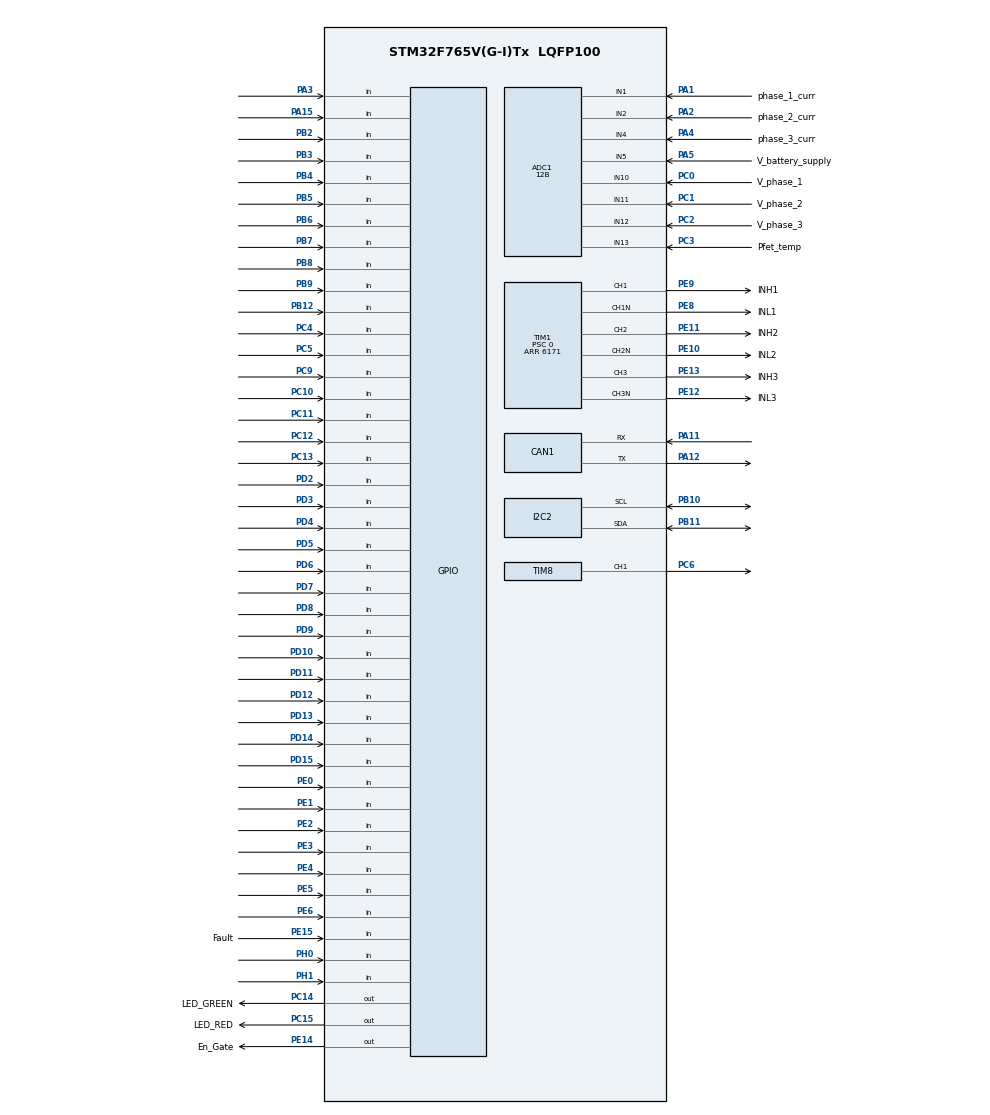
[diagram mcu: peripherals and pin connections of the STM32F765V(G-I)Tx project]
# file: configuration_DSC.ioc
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ADC1.Channel-0\#ChannelRegularConversion=ADC_CHANNEL_1
ADC1.Channel-1\#ChannelRegularConversion=ADC_CHANNEL_1
ADC1.Channel-2\#ChannelRegularConversion=ADC_CHANNEL_1
ADC1.Channel-3\#ChannelRegularConversion=ADC_CHANNEL_1
ADC1.Channel-4\#ChannelRegularConversion=ADC_CHANNEL_1
ADC1.Channel-5\#ChannelRegularConversion=ADC_CHANNEL_1
ADC1.Channel-6\#ChannelRegularConversion=ADC_CHANNEL_1
ADC1.Channel-7\#ChannelRegularConversion=ADC_CHANNEL_1
ADC1.EOCSelection=ADC_EOC_SEQ_CONV
ADC1.ExternalTrigConv=ADC_EXTERNALTRIGCONV_T8_TRGO
ADC1.ExternalTrigConvEdge=ADC_EXTERNALTRIGCONVEDGE_FALLING
ADC1.NbrOfConversion=8
ADC1.NbrOfConversionFlag=1
ADC1.Rank-0\#ChannelRegularConversion=1
ADC1.Rank-1\#ChannelRegularConversion=2
ADC1.Rank-2\#ChannelRegularConversion=3
ADC1.Rank-3\#ChannelRegularConversion=4
ADC1.Rank-4\#ChannelRegularConversion=5
ADC1.Rank-5\#ChannelRegularConversion=6
ADC1.Rank-6\#ChannelRegularConversion=7
ADC1.Rank-7\#ChannelRegularConversion=8
ADC1.Resolution=ADC_RESOLUTION_12B
ADC1.SamplingTime-0\#ChannelRegularConversion=ADC_SAMPLETIME_3CYCLES
ADC1.SamplingTime-1\#ChannelRegularConversion=ADC_SAMPLETIME_3CYCLES
ADC1.SamplingTime-2\#ChannelRegularConversion=ADC_SAMPLETIME_3CYCLES
ADC1.SamplingTime-3\#ChannelRegularConversion=ADC_SAMPLETIME_3CYCLES
ADC1.SamplingTime-4\#ChannelRegularConversion=ADC_SAMPLETIME_3CYCLES
ADC1.SamplingTime-5\#ChannelRegularConversion=ADC_SAMPLETIME_3CYCLES
ADC1.SamplingTime-6\#ChannelRegularConversion=ADC_SAMPLETIME_3CYCLES
ADC1.SamplingTime-7\#ChannelRegularConversion=ADC_SAMPLETIME_3CYCLES
ADC1.master=1
CAN1.CalculateTimeQuantum=1000.0
Dma.ADC1.0.Direction=DMA_PERIPH_TO_MEMORY
Dma.ADC1.0.FIFOMode=DMA_FIFOMODE_DISABLE
Dma.ADC1.0.Instance=DMA2_Stream0
Dma.ADC1.0.MemDataAlignment=DMA_MDATAALIGN_HALFWORD
Dma.ADC1.0.MemInc=DMA_MINC_ENABLE
Dma.ADC1.0.Mode=DMA_CIRCULAR
Dma.ADC1.0.PeriphDataAlignment=DMA_PDATAALIGN_HALFWORD
Dma.ADC1.0.PeriphInc=DMA_PINC_DISABLE
Dma.ADC1.0.Priority=DMA_PRIORITY_HIGH
Dma.Request0=ADC1
Mcu.Family=STM32F7
Mcu.Name=STM32F765V(G-I)Tx
Mcu.Package=LQFP100
NVIC.ADC_IRQn=true\:0\:0\:false\:false\:true\:true\:true
NVIC.DMA2_Stream0_IRQn=true\:0\:0\:false\:false\:true\:false\:true
NVIC.PriorityGroup=NVIC_PRIORITYGROUP_4
PA1.GPIO_Label=phase_1_curr
PA1.Signal=ADCx_IN1
PA11.Mode=Master
PA11.Signal=CAN1_RX
PA12.Mode=Master
PA12.Signal=CAN1_TX
PA13.Signal=SYS_JTMS-SWDIO
PA14.Signal=SYS_JTCK-SWCLK
PA15.GPIO_PuPd=GPIO_PULLDOWN
PA15.Signal=GPIO_Input
PA2.GPIO_Label=phase_2_curr
PA2.Signal=ADCx_IN2
PA3.GPIO_PuPd=GPIO_PULLDOWN
PA3.Signal=GPIO_Input
PA4.GPIO_Label=phase_3_curr
PA4.Signal=ADCx_IN4
PA5.GPIO_Label=V_battery_supply
PA5.Signal=ADCx_IN5
PB10.Mode=I2C
PB10.Signal=I2C2_SCL
PB11.Mode=I2C
PB11.Signal=I2C2_SDA
PB12.GPIO_PuPd=GPIO_PULLDOWN
PB12.Signal=GPIO_Input
PB2.GPIO_PuPd=GPIO_PULLDOWN
PB2.Signal=GPIO_Input
PB3.GPIO_PuPd=GPIO_PULLDOWN
PB3.Signal=GPIO_Input
PB4.GPIO_PuPd=GPIO_PULLDOWN
PB4.Signal=GPIO_Input
PB5.GPIO_PuPd=GPIO_PULLDOWN
PB5.Signal=GPIO_Input
PB6.GPIO_PuPd=GPIO_PULLDOWN
PB6.Signal=GPIO_Input
PB7.GPIO_PuPd=GPIO_PULLDOWN
PB7.Signal=GPIO_Input
PB8.GPIO_PuPd=GPIO_PULLDOWN
PB8.Signal=GPIO_Input
PB9.GPIO_PuPd=GPIO_PULLDOWN
PB9.Signal=GPIO_Input
PC0.GPIO_Label=V_phase_1
PC0.Signal=ADCx_IN10
PC1.GPIO_Label=V_phase_2
PC1.Signal=ADCx_IN11
PC10.GPIO_PuPd=GPIO_PULLDOWN
PC10.Signal=GPIO_Input
PC11.GPIO_PuPd=GPIO_PULLDOWN
PC11.Signal=GPIO_Input
PC12.GPIO_PuPd=GPIO_PULLDOWN
PC12.Signal=GPIO_Input
PC13.GPIO_PuPd=GPIO_PULLDOWN
PC13.Signal=GPIO_Input
PC14/OSC32_IN.GPIO_Label=LED_GREEN
PC14/OSC32_IN.GPIO_PuPd=GPIO_PULLUP
PC14/OSC32_IN.Signal=GPIO_Output
PC15/OSC32_OUT.GPIO_Label=LED_RED
PC15/OSC32_OUT.GPIO_PuPd=GPIO_PULLUP
PC15/OSC32_OUT.Signal=GPIO_Output
PC2.GPIO_Label=V_phase_3
PC2.Signal=ADCx_IN12
PC3.GPIO_Label=Pfet_temp
PC3.Signal=ADCx_IN13
PC4.GPIO_PuPd=GPIO_PULLDOWN
PC4.Signal=GPIO_Input
PC5.GPIO_PuPd=GPIO_PULLDOWN
PC5.Signal=GPIO_Input
PC6.Signal=S_TIM8_CH1
PC9.GPIO_PuPd=GPIO_PULLDOWN
PC9.Signal=GPIO_Input
PD10.GPIO_PuPd=GPIO_PULLDOWN
PD10.Signal=GPIO_Input
PD11.GPIO_PuPd=GPIO_PULLDOWN
PD11.Signal=GPIO_Input
PD12.GPIO_PuPd=GPIO_PULLDOWN
PD12.Signal=GPIO_Input
PD13.GPIO_PuPd=GPIO_PULLDOWN
PD13.Signal=GPIO_Input
PD14.Signal=GPIO_Input
PD15.GPIO_PuPd=GPIO_PULLDOWN
PD15.Signal=GPIO_Input
PD2.GPIO_PuPd=GPIO_PULLDOWN
PD2.Signal=GPIO_Input
PD3.GPIO_PuPd=GPIO_PULLDOWN
PD3.Signal=GPIO_Input
PD4.GPIO_PuPd=GPIO_PULLDOWN
PD4.Signal=GPIO_Input
PD5.GPIO_PuPd=GPIO_PULLDOWN
PD5.Signal=GPIO_Input
PD6.GPIO_PuPd=GPIO_PULLDOWN
PD6.Signal=GPIO_Input
PD7.GPIO_PuPd=GPIO_PULLDOWN
PD7.Signal=GPIO_Input
PD8.GPIO_PuPd=GPIO_PULLDOWN
PD8.Signal=GPIO_Input
PD9.GPIO_PuPd=GPIO_PULLDOWN
PD9.Signal=GPIO_Input
PE0.GPIO_PuPd=GPIO_PULLDOWN
PE0.Signal=GPIO_Input
PE1.GPIO_PuPd=GPIO_PULLDOWN
PE1.Signal=GPIO_Input
PE10.GPIO_Label=INL2
PE10.Mode=PWM Generation2 CH2 CH2N
PE10.Signal=TIM1_CH2N
PE11.GPIO_Label=INH2
PE11.Signal=S_TIM1_CH2
PE12.GPIO_Label=INL3
PE12.Mode=PWM Generation3 CH3 CH3N
PE12.Signal=TIM1_CH3N
PE13.GPIO_Label=INH3
PE13.Signal=S_TIM1_CH3
PE14.GPIO_Label=En_Gate
PE14.GPIO_PuPd=GPIO_PULLUP
PE14.Signal=GPIO_Output
PE15.GPIO_Label=Fault
PE15.GPIO_PuPd=GPIO_PULLUP
PE15.Signal=GPIO_Input
PE2.GPIO_PuPd=GPIO_PULLDOWN
PE2.Signal=GPIO_Input
PE3.GPIO_PuPd=GPIO_PULLDOWN
PE3.Signal=GPIO_Input
PE4.GPIO_PuPd=GPIO_PULLDOWN
PE4.Signal=GPIO_Input
PE5.GPIO_PuPd=GPIO_PULLDOWN
PE5.Signal=GPIO_Input
PE6.GPIO_PuPd=GPIO_PULLDOWN
PE6.Signal=GPIO_Input
PE8.GPIO_Label=INL1
PE8.Mode=PWM Generation1 CH1 CH1N
PE8.Signal=TIM1_CH1N
PE9.GPIO_Label=INH1
PE9.Signal=S_TIM1_CH1
PH0/OSC_IN.GPIO_PuPd=GPIO_PULLDOWN
PH0/OSC_IN.Signal=GPIO_Input
PH1/OSC_OUT.GPIO_PuPd=GPIO_PULLDOWN
PH1/OSC_OUT.Signal=GPIO_Input
ProjectManager.HeapSize=0x200
ProjectManager.StackSize=0x400
ProjectManager.TargetToolchain=STM32CubeIDE
RCC.HSE_VALUE=25000000
RCC.HSI_VALUE=16000000
RCC.LSE_VALUE=32768
RCC.USBFreq_Value=96000000
RCC.VCOOutputFreq_Value=192000000
SH.ADCx_IN1.0=ADC1_IN1,IN1
SH.ADCx_IN10.0=ADC1_IN10,IN10
SH.ADCx_IN11.0=ADC1_IN11,IN11
SH.ADCx_IN12.0=ADC1_IN12,IN12
SH.ADCx_IN13.0=ADC1_IN13,IN13
SH.ADCx_IN2.0=ADC1_IN2,IN2
SH.ADCx_IN4.0=ADC1_IN4,IN4
SH.ADCx_IN5.0=ADC1_IN5,IN5
SH.S_TIM1_CH1.0=TIM1_CH1,PWM Generation1 CH1 CH1N
SH.S_TIM1_CH2.0=TIM1_CH2,PWM Generation2 CH2 CH2N
SH.S_TIM1_CH3.0=TIM1_CH3,PWM Generation3 CH3 CH3N
SH.S_TIM8_CH1.0=TIM8_CH1,Forced Output1 CH1
TIM1.Channel-PWM\ Generation1\ CH1\ CH1N=TIM_CHANNEL_1
TIM1.Channel-PWM\ Generation2\ CH2\ CH2N=TIM_CHANNEL_2
TIM1.Channel-PWM\ Generation3\ CH3\ CH3N=TIM_CHANNEL_3
TIM1.CounterMode=TIM_COUNTERMODE_UP
TIM1.DeadTime=78
TIM1.OCIdleState_1=TIM_OCIDLESTATE_SET
TIM1.OCIdleState_2=TIM_OCIDLESTATE_SET
TIM1.OCIdleState_3=TIM_OCIDLESTATE_SET
TIM1.OCNIdleState_1=TIM_OCNIDLESTATE_SET
TIM1.OCNIdleState_2=TIM_OCNIDLESTATE_SET
TIM1.OCNIdleState_3=TIM_OCNIDLESTATE_SET
TIM1.OffStateIDLEMode=TIM_OSSI_ENABLE
TIM1.OffStateRunMode=TIM_OSSR_ENABLE
TIM1.Period=6171
TIM1.Prescaler=0
TIM1.Pulse-PWM\ Generation1\ CH1\ CH1N=3085
TIM1.Pulse-PWM\ Generation2\ CH2\ CH2N=3085
TIM1.Pulse-PWM\ Generation3\ CH3\ CH3N=3085
TIM8.Channel-Forced\ Output1\ CH1=TIM_CHANNEL_1
TIM8.Period=0xffff
VP_TIM1_VS_ClockSourceINT.Mode=Internal
VP_TIM8_VS_ClockSourceITR.Mode=TriggerSource_ITR0
VP_TIM8_VS_ControllerModeReset.Mode=Reset Mode
board=custom

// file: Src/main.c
/* USER CODE BEGIN Header */
/**
  ******************************************************************************
  * @file           : main.c
  * @brief          : Main program body
  ******************************************************************************
  * @attention
  *
  * <h2><center>&copy; Copyright (c) 2019 STMicroelectronics.
  * All rights reserved.</center></h2>
  *
  * This software component is licensed by ST under BSD 3-Clause license,
  * the "License"; You may not use this file except in compliance with the
  * License. You may obtain a copy of the License at:
  *                        opensource.org/licenses/BSD-3-Clause
  *
  ******************************************************************************
  */
/* USER CODE END Header */

#include "main.h"

ADC_HandleTypeDef hadc1;
DMA_HandleTypeDef hdma_adc1;

CAN_HandleTypeDef hcan1;

I2C_HandleTypeDef hi2c2;

TIM_HandleTypeDef htim1;
TIM_HandleTypeDef htim8;

void SystemClock_Config(void);
static void MX_GPIO_Init(void);
static void MX_DMA_Init(void);
static void MX_ADC1_Init(void);
static void MX_CAN1_Init(void);
static void MX_I2C2_Init(void);
static void MX_TIM1_Init(void);
static void MX_TIM8_Init(void);

int main(void)
{

  /* MCU Configuration--------------------------------------------------------*/

  /* Reset of all peripherals, Initializes the Flash interface and the Systick. */
  HAL_Init();

  /* Configure the system clock */
  SystemClock_Config();

  /* Initialize all configured peripherals */
  MX_GPIO_Init();
  MX_DMA_Init();
  MX_ADC1_Init();
  MX_CAN1_Init();
  MX_I2C2_Init();
  MX_TIM1_Init();
  MX_TIM8_Init();

  /* Infinite loop */
  /* USER CODE BEGIN WHILE */

  //Communicate with other micro-controllers and determine that they are online and functioning
  //Do calibration process than wait to get up to speed.
  //

  while (1)
  {
    /* USER CODE END WHILE */

  }
}

void SystemClock_Config(void)
{
  RCC_OscInitTypeDef RCC_OscInitStruct = {0};
  RCC_ClkInitTypeDef RCC_ClkInitStruct = {0};
  RCC_PeriphCLKInitTypeDef PeriphClkInitStruct = {0};

  /** Configure the main internal regulator output voltage
  */
  __HAL_RCC_PWR_CLK_ENABLE();
  __HAL_PWR_VOLTAGESCALING_CONFIG(PWR_REGULATOR_VOLTAGE_SCALE3);
  /** Initializes the CPU, AHB and APB busses clocks
  */
  RCC_OscInitStruct.OscillatorType = RCC_OSCILLATORTYPE_HSI;
  RCC_OscInitStruct.HSIState = RCC_HSI_ON;
  RCC_OscInitStruct.HSICalibrationValue = RCC_HSICALIBRATION_DEFAULT;
  RCC_OscInitStruct.PLL.PLLState = RCC_PLL_NONE;
  if (HAL_RCC_OscConfig(&RCC_OscInitStruct) != HAL_OK)
  {
    Error_Handler();
  }
  /** Initializes the CPU, AHB and APB busses clocks
  */
  RCC_ClkInitStruct.ClockType = RCC_CLOCKTYPE_HCLK|RCC_CLOCKTYPE_SYSCLK
                              |RCC_CLOCKTYPE_PCLK1|RCC_CLOCKTYPE_PCLK2;
  RCC_ClkInitStruct.SYSCLKSource = RCC_SYSCLKSOURCE_HSI;
  RCC_ClkInitStruct.AHBCLKDivider = RCC_SYSCLK_DIV1;
  RCC_ClkInitStruct.APB1CLKDivider = RCC_HCLK_DIV1;
  RCC_ClkInitStruct.APB2CLKDivider = RCC_HCLK_DIV1;

  if (HAL_RCC_ClockConfig(&RCC_ClkInitStruct, FLASH_LATENCY_0) != HAL_OK)
  {
    Error_Handler();
  }
  PeriphClkInitStruct.PeriphClockSelection = RCC_PERIPHCLK_I2C2;
  PeriphClkInitStruct.I2c2ClockSelection = RCC_I2C2CLKSOURCE_PCLK1;
  if (HAL_RCCEx_PeriphCLKConfig(&PeriphClkInitStruct) != HAL_OK)
  {
    Error_Handler();
  }
}

static void MX_ADC1_Init(void)
{

  ADC_ChannelConfTypeDef sConfig = {0};

  /** Configure the global features of the ADC (Clock, Resolution, Data Alignment and number of conversion)
  */
  hadc1.Instance = ADC1;
  hadc1.Init.ClockPrescaler = ADC_CLOCK_SYNC_PCLK_DIV2;
  hadc1.Init.Resolution = ADC_RESOLUTION_12B;
  hadc1.Init.ScanConvMode = ENABLE;
  hadc1.Init.ContinuousConvMode = DISABLE;
  hadc1.Init.DiscontinuousConvMode = DISABLE;
  hadc1.Init.ExternalTrigConvEdge = ADC_EXTERNALTRIGCONVEDGE_FALLING;
  hadc1.Init.ExternalTrigConv = ADC_EXTERNALTRIGCONV_T8_TRGO;
  hadc1.Init.DataAlign = ADC_DATAALIGN_RIGHT;
  hadc1.Init.NbrOfConversion = 8;
  hadc1.Init.DMAContinuousRequests = DISABLE;
  hadc1.Init.EOCSelection = ADC_EOC_SEQ_CONV;
  if (HAL_ADC_Init(&hadc1) != HAL_OK)
  {
    Error_Handler();
  }
  /** Configure for the selected ADC regular channel its corresponding rank in the sequencer and its sample time.
  */
  sConfig.Channel = ADC_CHANNEL_1;
  sConfig.Rank = ADC_REGULAR_RANK_1;
  sConfig.SamplingTime = ADC_SAMPLETIME_3CYCLES;
  if (HAL_ADC_ConfigChannel(&hadc1, &sConfig) != HAL_OK)
  {
    Error_Handler();
  }
  /** Configure for the selected ADC regular channel its corresponding rank in the sequencer and its sample time.
  */
  sConfig.Rank = ADC_REGULAR_RANK_2;
  if (HAL_ADC_ConfigChannel(&hadc1, &sConfig) != HAL_OK)
  {
    Error_Handler();
  }
  /** Configure for the selected ADC regular channel its corresponding rank in the sequencer and its sample time.
  */
  sConfig.Rank = ADC_REGULAR_RANK_3;
  if (HAL_ADC_ConfigChannel(&hadc1, &sConfig) != HAL_OK)
  {
    Error_Handler();
  }
  /** Configure for the selected ADC regular channel its corresponding rank in the sequencer and its sample time.
  */
  sConfig.Rank = ADC_REGULAR_RANK_4;
  if (HAL_ADC_ConfigChannel(&hadc1, &sConfig) != HAL_OK)
  {
    Error_Handler();
  }
  /** Configure for the selected ADC regular channel its corresponding rank in the sequencer and its sample time.
  */
  sConfig.Rank = ADC_REGULAR_RANK_5;
  if (HAL_ADC_ConfigChannel(&hadc1, &sConfig) != HAL_OK)
  {
    Error_Handler();
  }
  /** Configure for the selected ADC regular channel its corresponding rank in the sequencer and its sample time.
  */
  sConfig.Rank = ADC_REGULAR_RANK_6;
  if (HAL_ADC_ConfigChannel(&hadc1, &sConfig) != HAL_OK)
  {
    Error_Handler();
  }
  /** Configure for the selected ADC regular channel its corresponding rank in the sequencer and its sample time.
  */
  sConfig.Rank = ADC_REGULAR_RANK_7;
  if (HAL_ADC_ConfigChannel(&hadc1, &sConfig) != HAL_OK)
  {
    Error_Handler();
  }
  /** Configure for the selected ADC regular channel its corresponding rank in the sequencer and its sample time.
  */
  sConfig.Rank = ADC_REGULAR_RANK_8;
  if (HAL_ADC_ConfigChannel(&hadc1, &sConfig) != HAL_OK)
  {
    Error_Handler();
  }

}

static void MX_CAN1_Init(void)
{

  hcan1.Instance = CAN1;
  hcan1.Init.Prescaler = 16;
  hcan1.Init.Mode = CAN_MODE_NORMAL;
  hcan1.Init.SyncJumpWidth = CAN_SJW_1TQ;
  hcan1.Init.TimeSeg1 = CAN_BS1_1TQ;
  hcan1.Init.TimeSeg2 = CAN_BS2_1TQ;
  hcan1.Init.TimeTriggeredMode = DISABLE;
  hcan1.Init.AutoBusOff = DISABLE;
  hcan1.Init.AutoWakeUp = DISABLE;
  hcan1.Init.AutoRetransmission = DISABLE;
  hcan1.Init.ReceiveFifoLocked = DISABLE;
  hcan1.Init.TransmitFifoPriority = DISABLE;
  if (HAL_CAN_Init(&hcan1) != HAL_OK)
  {
    Error_Handler();
  }

}

static void MX_I2C2_Init(void)
{

  hi2c2.Instance = I2C2;
  hi2c2.Init.Timing = 0x00303D5B;
  hi2c2.Init.OwnAddress1 = 0;
  hi2c2.Init.AddressingMode = I2C_ADDRESSINGMODE_7BIT;
  hi2c2.Init.DualAddressMode = I2C_DUALADDRESS_DISABLE;
  hi2c2.Init.OwnAddress2 = 0;
  hi2c2.Init.OwnAddress2Masks = I2C_OA2_NOMASK;
  hi2c2.Init.GeneralCallMode = I2C_GENERALCALL_DISABLE;
  hi2c2.Init.NoStretchMode = I2C_NOSTRETCH_DISABLE;
  if (HAL_I2C_Init(&hi2c2) != HAL_OK)
  {
    Error_Handler();
  }
  /** Configure Analogue filter
  */
  if (HAL_I2CEx_ConfigAnalogFilter(&hi2c2, I2C_ANALOGFILTER_ENABLE) != HAL_OK)
  {
    Error_Handler();
  }
  /** Configure Digital filter
  */
  if (HAL_I2CEx_ConfigDigitalFilter(&hi2c2, 0) != HAL_OK)
  {
    Error_Handler();
  }

}

static void MX_TIM1_Init(void)
{

  TIM_ClockConfigTypeDef sClockSourceConfig = {0};
  TIM_MasterConfigTypeDef sMasterConfig = {0};
  TIM_OC_InitTypeDef sConfigOC = {0};
  TIM_BreakDeadTimeConfigTypeDef sBreakDeadTimeConfig = {0};

  htim1.Instance = TIM1;
  htim1.Init.Prescaler = 0;
  htim1.Init.CounterMode = TIM_COUNTERMODE_UP;
  htim1.Init.Period = 6171;
  htim1.Init.ClockDivision = TIM_CLOCKDIVISION_DIV1;
  htim1.Init.RepetitionCounter = 0;
  htim1.Init.AutoReloadPreload = TIM_AUTORELOAD_PRELOAD_DISABLE;
  if (HAL_TIM_Base_Init(&htim1) != HAL_OK)
  {
    Error_Handler();
  }
  sClockSourceConfig.ClockSource = TIM_CLOCKSOURCE_INTERNAL;
  if (HAL_TIM_ConfigClockSource(&htim1, &sClockSourceConfig) != HAL_OK)
  {
    Error_Handler();
  }
  if (HAL_TIM_PWM_Init(&htim1) != HAL_OK)
  {
    Error_Handler();
  }
  sMasterConfig.MasterOutputTrigger = TIM_TRGO_RESET;
  sMasterConfig.MasterOutputTrigger2 = TIM_TRGO2_RESET;
  sMasterConfig.MasterSlaveMode = TIM_MASTERSLAVEMODE_DISABLE;
  if (HAL_TIMEx_MasterConfigSynchronization(&htim1, &sMasterConfig) != HAL_OK)
  {
    Error_Handler();
  }
  sConfigOC.OCMode = TIM_OCMODE_PWM1;
  sConfigOC.Pulse = 3085;
  sConfigOC.OCPolarity = TIM_OCPOLARITY_HIGH;
  sConfigOC.OCNPolarity = TIM_OCNPOLARITY_HIGH;
  sConfigOC.OCFastMode = TIM_OCFAST_DISABLE;
  sConfigOC.OCIdleState = TIM_OCIDLESTATE_SET;
  sConfigOC.OCNIdleState = TIM_OCNIDLESTATE_SET;
  if (HAL_TIM_PWM_ConfigChannel(&htim1, &sConfigOC, TIM_CHANNEL_1) != HAL_OK)
  {
    Error_Handler();
  }
  if (HAL_TIM_PWM_ConfigChannel(&htim1, &sConfigOC, TIM_CHANNEL_2) != HAL_OK)
  {
    Error_Handler();
  }
  if (HAL_TIM_PWM_ConfigChannel(&htim1, &sConfigOC, TIM_CHANNEL_3) != HAL_OK)
  {
    Error_Handler();
  }
  sBreakDeadTimeConfig.OffStateRunMode = TIM_OSSR_ENABLE;
  sBreakDeadTimeConfig.OffStateIDLEMode = TIM_OSSI_ENABLE;
  sBreakDeadTimeConfig.LockLevel = TIM_LOCKLEVEL_OFF;
  sBreakDeadTimeConfig.DeadTime = 78;
  sBreakDeadTimeConfig.BreakState = TIM_BREAK_DISABLE;
  sBreakDeadTimeConfig.BreakPolarity = TIM_BREAKPOLARITY_HIGH;
  sBreakDeadTimeConfig.BreakFilter = 0;
  sBreakDeadTimeConfig.Break2State = TIM_BREAK2_DISABLE;
  sBreakDeadTimeConfig.Break2Polarity = TIM_BREAK2POLARITY_HIGH;
  sBreakDeadTimeConfig.Break2Filter = 0;
  sBreakDeadTimeConfig.AutomaticOutput = TIM_AUTOMATICOUTPUT_DISABLE;
  if (HAL_TIMEx_ConfigBreakDeadTime(&htim1, &sBreakDeadTimeConfig) != HAL_OK)
  {
    Error_Handler();
  }
  HAL_TIM_MspPostInit(&htim1);

}

static void MX_TIM8_Init(void)
{

  TIM_SlaveConfigTypeDef sSlaveConfig = {0};
  TIM_MasterConfigTypeDef sMasterConfig = {0};
  TIM_OC_InitTypeDef sConfigOC = {0};
  TIM_BreakDeadTimeConfigTypeDef sBreakDeadTimeConfig = {0};

  htim8.Instance = TIM8;
  htim8.Init.Prescaler = 0;
  htim8.Init.CounterMode = TIM_COUNTERMODE_UP;
  htim8.Init.Period = 0xffff;
  htim8.Init.ClockDivision = TIM_CLOCKDIVISION_DIV1;
  htim8.Init.RepetitionCounter = 0;
  htim8.Init.AutoReloadPreload = TIM_AUTORELOAD_PRELOAD_DISABLE;
  if (HAL_TIM_Base_Init(&htim8) != HAL_OK)
  {
    Error_Handler();
  }
  if (HAL_TIM_OC_Init(&htim8) != HAL_OK)
  {
    Error_Handler();
  }
  sSlaveConfig.SlaveMode = TIM_SLAVEMODE_RESET;
  sSlaveConfig.InputTrigger = TIM_TS_ITR0;
  if (HAL_TIM_SlaveConfigSynchro(&htim8, &sSlaveConfig) != HAL_OK)
  {
    Error_Handler();
  }
  sMasterConfig.MasterOutputTrigger = TIM_TRGO_RESET;
  sMasterConfig.MasterOutputTrigger2 = TIM_TRGO2_RESET;
  sMasterConfig.MasterSlaveMode = TIM_MASTERSLAVEMODE_DISABLE;
  if (HAL_TIMEx_MasterConfigSynchronization(&htim8, &sMasterConfig) != HAL_OK)
  {
    Error_Handler();
  }
  sConfigOC.OCMode = TIM_OCMODE_FORCED_ACTIVE;
  sConfigOC.Pulse = 0;
  sConfigOC.OCPolarity = TIM_OCPOLARITY_HIGH;
  sConfigOC.OCNPolarity = TIM_OCNPOLARITY_HIGH;
  sConfigOC.OCFastMode = TIM_OCFAST_DISABLE;
  sConfigOC.OCIdleState = TIM_OCIDLESTATE_RESET;
  sConfigOC.OCNIdleState = TIM_OCNIDLESTATE_RESET;
  if (HAL_TIM_OC_ConfigChannel(&htim8, &sConfigOC, TIM_CHANNEL_1) != HAL_OK)
  {
    Error_Handler();
  }
  sBreakDeadTimeConfig.OffStateRunMode = TIM_OSSR_DISABLE;
  sBreakDeadTimeConfig.OffStateIDLEMode = TIM_OSSI_DISABLE;
  sBreakDeadTimeConfig.LockLevel = TIM_LOCKLEVEL_OFF;
  sBreakDeadTimeConfig.DeadTime = 0;
  sBreakDeadTimeConfig.BreakState = TIM_BREAK_DISABLE;
  sBreakDeadTimeConfig.BreakPolarity = TIM_BREAKPOLARITY_HIGH;
  sBreakDeadTimeConfig.BreakFilter = 0;
  sBreakDeadTimeConfig.Break2State = TIM_BREAK2_DISABLE;
  sBreakDeadTimeConfig.Break2Polarity = TIM_BREAK2POLARITY_HIGH;
  sBreakDeadTimeConfig.Break2Filter = 0;
  sBreakDeadTimeConfig.AutomaticOutput = TIM_AUTOMATICOUTPUT_DISABLE;
  if (HAL_TIMEx_ConfigBreakDeadTime(&htim8, &sBreakDeadTimeConfig) != HAL_OK)
  {
    Error_Handler();
  }
  HAL_TIM_MspPostInit(&htim8);

}

static void MX_DMA_Init(void)
{
  /* DMA controller clock enable */
  __HAL_RCC_DMA2_CLK_ENABLE();

  /* DMA interrupt init */
  /* DMA2_Stream0_IRQn interrupt configuration */
  HAL_NVIC_SetPriority(DMA2_Stream0_IRQn, 0, 0);
  HAL_NVIC_EnableIRQ(DMA2_Stream0_IRQn);

}

static void MX_GPIO_Init(void)
{
  GPIO_InitTypeDef GPIO_InitStruct = {0};

  /* GPIO Ports Clock Enable */
  __HAL_RCC_GPIOE_CLK_ENABLE();
  __HAL_RCC_GPIOC_CLK_ENABLE();
  __HAL_RCC_GPIOH_CLK_ENABLE();
  __HAL_RCC_GPIOA_CLK_ENABLE();
  __HAL_RCC_GPIOB_CLK_ENABLE();
  __HAL_RCC_GPIOD_CLK_ENABLE();

  /*Configure GPIO pin Output Level */
  HAL_GPIO_WritePin(GPIOC, LED_GREEN_Pin|LED_RED_Pin, GPIO_PIN_RESET);

  /*Configure GPIO pin Output Level */
  HAL_GPIO_WritePin(En_Gate_GPIO_Port, En_Gate_Pin, GPIO_PIN_RESET);

  /*Configure GPIO pins : PE2 PE3 PE4 PE5
                           PE6 PE0 PE1 */
  GPIO_InitStruct.Pin = GPIO_PIN_2|GPIO_PIN_3|GPIO_PIN_4|GPIO_PIN_5
                          |GPIO_PIN_6|GPIO_PIN_0|GPIO_PIN_1;
  GPIO_InitStruct.Mode = GPIO_MODE_INPUT;
  GPIO_InitStruct.Pull = GPIO_PULLDOWN;
  HAL_GPIO_Init(GPIOE, &GPIO_InitStruct);

  /*Configure GPIO pins : PC13 PC4 PC5 PC9
                           PC10 PC11 PC12 */
  GPIO_InitStruct.Pin = GPIO_PIN_13|GPIO_PIN_4|GPIO_PIN_5|GPIO_PIN_9
                          |GPIO_PIN_10|GPIO_PIN_11|GPIO_PIN_12;
  GPIO_InitStruct.Mode = GPIO_MODE_INPUT;
  GPIO_InitStruct.Pull = GPIO_PULLDOWN;
  HAL_GPIO_Init(GPIOC, &GPIO_InitStruct);

  /*Configure GPIO pins : LED_GREEN_Pin LED_RED_Pin */
  GPIO_InitStruct.Pin = LED_GREEN_Pin|LED_RED_Pin;
  GPIO_InitStruct.Mode = GPIO_MODE_OUTPUT_PP;
  GPIO_InitStruct.Pull = GPIO_PULLUP;
  GPIO_InitStruct.Speed = GPIO_SPEED_FREQ_LOW;
  HAL_GPIO_Init(GPIOC, &GPIO_InitStruct);

  /*Configure GPIO pins : PH0 PH1 */
  GPIO_InitStruct.Pin = GPIO_PIN_0|GPIO_PIN_1;
  GPIO_InitStruct.Mode = GPIO_MODE_INPUT;
  GPIO_InitStruct.Pull = GPIO_PULLDOWN;
  HAL_GPIO_Init(GPIOH, &GPIO_InitStruct);

  /*Configure GPIO pins : PA3 PA15 */
  GPIO_InitStruct.Pin = GPIO_PIN_3|GPIO_PIN_15;
  GPIO_InitStruct.Mode = GPIO_MODE_INPUT;
  GPIO_InitStruct.Pull = GPIO_PULLDOWN;
  HAL_GPIO_Init(GPIOA, &GPIO_InitStruct);

  /*Configure GPIO pins : PB2 PB12 PB3 PB4
                           PB5 PB6 PB7 PB8
                           PB9 */
  GPIO_InitStruct.Pin = GPIO_PIN_2|GPIO_PIN_12|GPIO_PIN_3|GPIO_PIN_4
                          |GPIO_PIN_5|GPIO_PIN_6|GPIO_PIN_7|GPIO_PIN_8
                          |GPIO_PIN_9;
  GPIO_InitStruct.Mode = GPIO_MODE_INPUT;
  GPIO_InitStruct.Pull = GPIO_PULLDOWN;
  HAL_GPIO_Init(GPIOB, &GPIO_InitStruct);

  /*Configure GPIO pin : En_Gate_Pin */
  GPIO_InitStruct.Pin = En_Gate_Pin;
  GPIO_InitStruct.Mode = GPIO_MODE_OUTPUT_PP;
  GPIO_InitStruct.Pull = GPIO_PULLUP;
  GPIO_InitStruct.Speed = GPIO_SPEED_FREQ_LOW;
  HAL_GPIO_Init(En_Gate_GPIO_Port, &GPIO_InitStruct);

  /*Configure GPIO pin : Fault_Pin */
  GPIO_InitStruct.Pin = Fault_Pin;
  GPIO_InitStruct.Mode = GPIO_MODE_INPUT;
  GPIO_InitStruct.Pull = GPIO_PULLUP;
  HAL_GPIO_Init(Fault_GPIO_Port, &GPIO_InitStruct);

  /*Configure GPIO pins : PD8 PD9 PD10 PD11
                           PD12 PD13 PD15 PD2
                           PD3 PD4 PD5 PD6
                           PD7 */
  GPIO_InitStruct.Pin = GPIO_PIN_8|GPIO_PIN_9|GPIO_PIN_10|GPIO_PIN_11
                          |GPIO_PIN_12|GPIO_PIN_13|GPIO_PIN_15|GPIO_PIN_2
                          |GPIO_PIN_3|GPIO_PIN_4|GPIO_PIN_5|GPIO_PIN_6
                          |GPIO_PIN_7;
  GPIO_InitStruct.Mode = GPIO_MODE_INPUT;
  GPIO_InitStruct.Pull = GPIO_PULLDOWN;
  HAL_GPIO_Init(GPIOD, &GPIO_InitStruct);

  /*Configure GPIO pin : PD14 */
  GPIO_InitStruct.Pin = GPIO_PIN_14;
  GPIO_InitStruct.Mode = GPIO_MODE_INPUT;
  GPIO_InitStruct.Pull = GPIO_NOPULL;
  HAL_GPIO_Init(GPIOD, &GPIO_InitStruct);

}

void Error_Handler(void)
{
}

/************************ (C) COPYRIGHT STMicroelectronics *****END OF FILE****/
